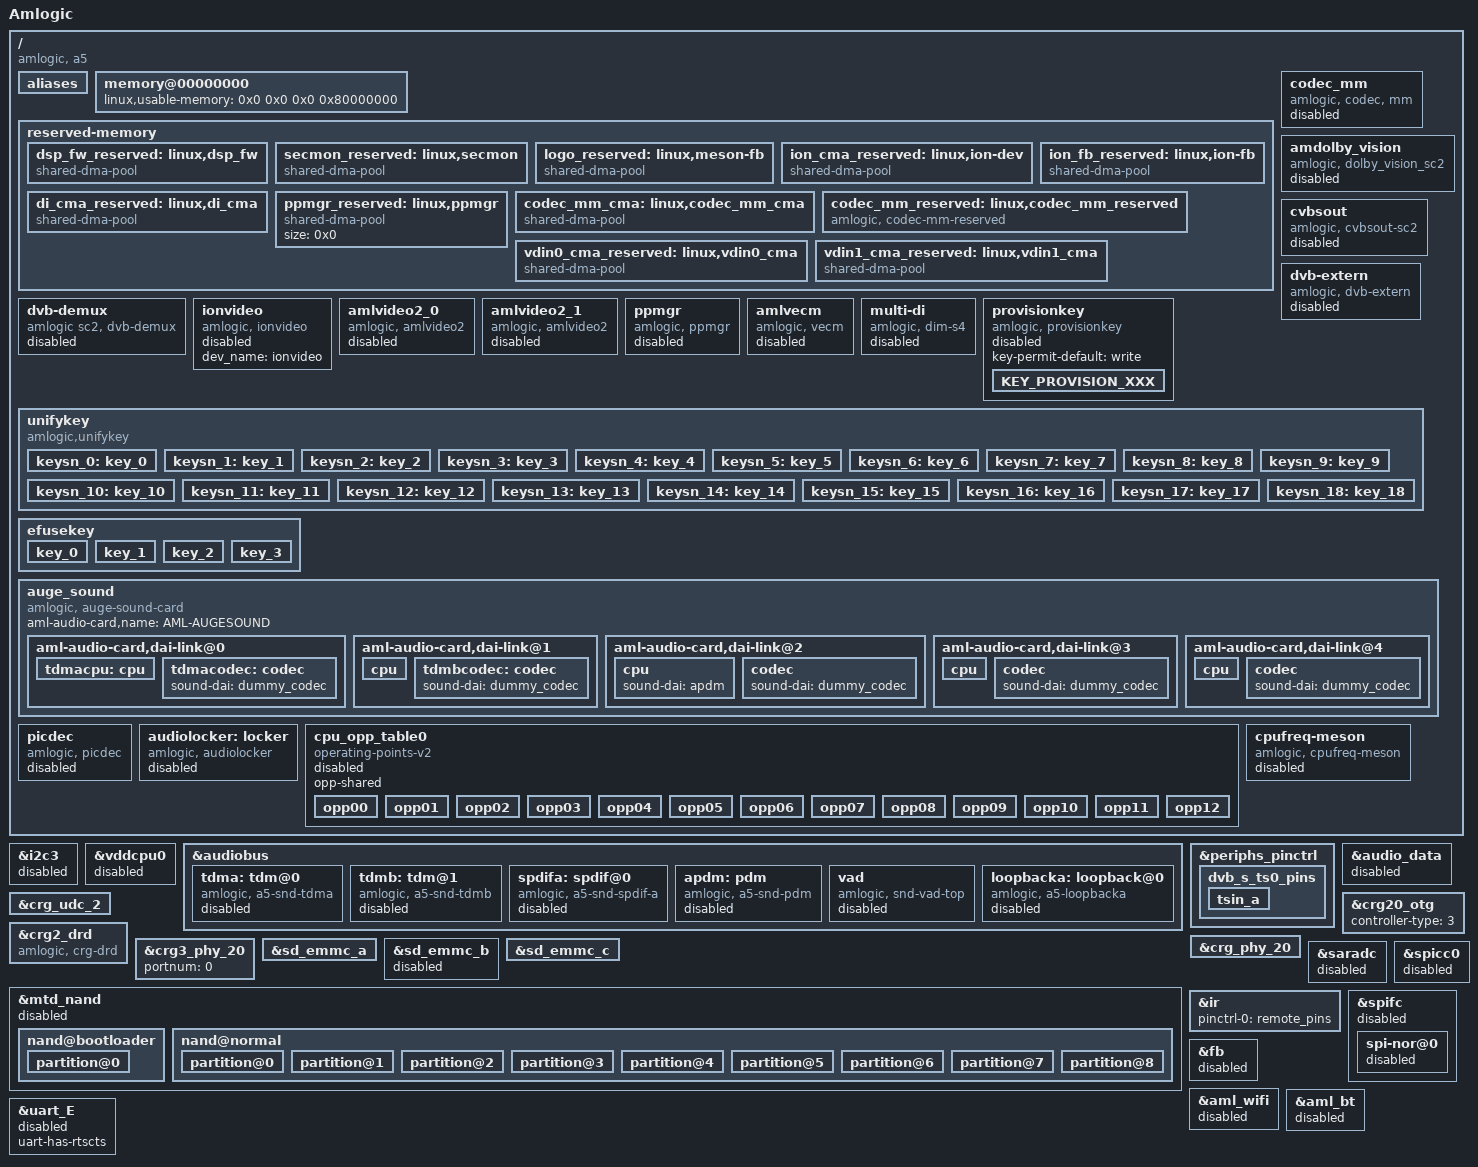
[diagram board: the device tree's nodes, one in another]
// SPDX-License-Identifier: (GPL-2.0+ OR MIT)
/*
 * Copyright (c) 2019 Amlogic, Inc. All rights reserved.
 */

/dts-v1/;

#include "meson-a5.dtsi"
#include "partition_mbox_ab.dtsi"
#include <dt-bindings/input/input.h>

/ {
	model = "Amlogic";
	amlogic-dt-id = "a5_pxp";
	compatible = "amlogic, a5";
	interrupt-parent = <&gic>;
	#address-cells = <2>;
	#size-cells = <2>;

	aliases {
		serial0 = &uart_B;
		serial1 = &uart_E;
		serial2 = &uart_C;
		serial3 = &uart_D;
		serial4 = &uart_A;
		i2c0 = &i2c0;
		i2c1 = &i2c1;
		i2c2 = &i2c2;
		i2c3 = &i2c3;
		spi0 = &spifc;
		spi1 = &spicc0;
		tsensor0 = &p_tsensor;
	};

	memory@00000000 {
		device_type = "memory";
		linux,usable-memory = <0x0 0x0 0x0 0x80000000>;
	};

	reserved-memory {
		#address-cells = <2>;
		#size-cells = <2>;
		ranges;

		dsp_fw_reserved:linux,dsp_fw {
			compatible = "shared-dma-pool";
			reusable;
			size = <0x0 0x00800000>;
			alignment = <0x0 0x00400000>;
			alloc-ranges = <0x0 0x30000000 0x0 0x00800000>;
		};

		secmon_reserved:linux,secmon {
			compatible = "shared-dma-pool";
			reusable;
			size = <0x0 0x3400000>;
			alignment = <0x0 0x400000>;
			alloc-ranges = <0x0 0x05000000 0x0 0x3400000>;
		};

		logo_reserved:linux,meson-fb {
			compatible = "shared-dma-pool";
			reusable;
			size = <0x0 0x800000>;
			alignment = <0x0 0x400000>;
			alloc-ranges = <0x0 0x7f800000 0x0 0x800000>;
		};

		ion_cma_reserved:linux,ion-dev {
			compatible = "shared-dma-pool";
			reusable;
			size = <0x0 0x6400000>;
			alignment = <0x0 0x400000>;
		};
		ion_fb_reserved:linux,ion-fb {
			compatible = "shared-dma-pool";
			reusable;
			/* 1920x1080x4x3 round up 4M align */
			size = <0x0 0x1c00000>;
			alignment = <0x0 0x400000>;
		};
		/*di CMA pool */
		di_cma_reserved:linux,di_cma {
			compatible = "shared-dma-pool";
			reusable;
			/* buffer_size = 3621952(yuv422 8bit)
			 *  | 4736064(yuv422 10bit)
			 *  | 4074560(yuv422 10bit full pack mode)
			 * 10x3621952=34.6M(0x23) support 8bit
			 * 10x4736064=45.2M(0x2e) support 12bit
			 * 10x4074560=40M(0x28) support 10bit
			 */
			//size = <0x0 0x0B000000>;
			//size = <0x0 0x0>;
			alignment = <0x0 0x400000>;
		};

		/*  POST PROCESS MANAGER */
		ppmgr_reserved:linux,ppmgr {
			compatible = "shared-dma-pool";
			size = <0x0>;
		};

		codec_mm_cma:linux,codec_mm_cma {
			compatible = "shared-dma-pool";
			reusable;
			/* ion_codec_mm max can alloc size 80M*/
			size = <0x0 0xd000000>;
			alignment = <0x0 0x400000>;
			linux,contiguous-region;
		};

		/* codec shared reserved */
		codec_mm_reserved:linux,codec_mm_reserved {
			compatible = "amlogic, codec-mm-reserved";
			size = <0x0 0x0>;
			alignment = <0x0 0x100000>;
			//no-map;
		};

		/*  vdin0 CMA pool */
		vdin0_cma_reserved:linux,vdin0_cma {
			compatible = "shared-dma-pool";
			reusable;
			/* up to 1920x1080 yuv422 8bit and 5 buffers
			 * 1920x1080x2x5 = 20 M
			 */
			size = <0x0 0x01400000>;
			alignment = <0x0 0x400000>;
		};
		/*  vdin1 CMA pool */
		vdin1_cma_reserved:linux,vdin1_cma {
			compatible = "shared-dma-pool";
			reusable;
			/* up to 1920x1080 yuv422 8bit and 5 buffers
			 * 1920x1080x2x5 = 20 M
			 */
			size = <0x0 0x01400000>;
			alignment = <0x0 0x400000>;
		};
	};
	codec_mm {
		compatible = "amlogic, codec, mm";
		memory-region = <&codec_mm_cma &codec_mm_reserved>;
		dev_name = "codec_mm";
		status = "disabled";
	};
	amdolby_vision {
		compatible = "amlogic, dolby_vision_sc2";
		dev_name = "aml_amdolby_vision_driver";
		status = "disabled";
		tv_mode = <0>;/*1:enabel ;0:disable*/
	};
	cvbsout {
		compatible = "amlogic, cvbsout-sc2";
		status = "disabled";

		/* clk path */
		/* 0:vid_pll vid2_clk */
		/* 1:gp0_pll vid2_clk */
		/* 2:vid_pll vid1_clk */
		/* 3:gp0_pll vid1_clk */
		clk_path = <0>;

		/* performance: reg_address, reg_value */
		/* tm2 */
		performance = <0x1bf0  0x9
			0x1b56  0x333
			0x1b12  0x8080
			0x1b05  0xfd
			0x1c59  0xf850
			0xffff  0x0>; /* ending flag */
		performance_sarft = <0x1bf0  0x9
			0x1b56  0x333
			0x1b12  0x0
			0x1b05  0x9
			0x1c59  0xfc48
			0xffff  0x0>; /* ending flag */
		performance_revB_telecom = <0x1bf0  0x9
			0x1b56  0x546
			0x1b12  0x8080
			0x1b05  0x9
			0x1c59  0xf850
			0xffff  0x0>; /* ending flag */
	};

	dvb-extern {
		compatible = "amlogic, dvb-extern";
		dev_name = "dvb-extern";
		status = "disabled";

		/* dvb hardware main power. */
		dvb_power_gpio = <&gpio GPIOZ_5 GPIO_ACTIVE_HIGH>;
		dvb_power_value = <1>;
		dvb_power_dir = <0>; /* 0: out, 1: in. */

		fe_num = <3>; /* interal 2 * dvb-c, extern 1 * dvb-s */
		fe0_demod = "internal";
		fe0_tuner0 = <0>; /* use tuner0 */

		fe1_demod = "internal";
		fe1_tuner0 = <1>; /* use tuner1 */

		fe2_demod = "cxd2856";
		//fe2_i2c_adap_id = <&i2c4>;
		fe2_demod_i2c_addr = <0xD8>;
		fe2_reset_value = <0>;
		fe2_reset_gpio = <&gpio GPIOZ_4 GPIO_ACTIVE_HIGH>;
		fe2_reset_dir = <0>; /* 0: out, 1: in. */
		fe2_ant_poweron_value = <0>;
		//fe2_ant_power_gpio = <&gpio GPIOH_9 GPIO_ACTIVE_HIGH>;
		fe2_ts = <0>;
		fe2_tuner1 = <3>; /* use tuner3, only S. */

		tuner_num = <4>; /* tuner number, multi tuner support */
		tuner0_name = "r836_tuner";
		tuner0_i2c_adap = <&i2c3>;
		tuner0_i2c_addr = <0x1a>; /* 7bit */
		tuner0_xtal = <0>; /* 0: 16MHz, 1: 24MHz */
		tuner0_xtal_mode = <0>;
					/* NO_SHARE_XTAL(0)
					 * SLAVE_XTAL_SHARE(3)
					 */
		tuner0_xtal_cap = <16>;
		tuner0_lt_out = <1>;

		tuner1_name = "r836_tuner";
		tuner1_i2c_adap = <&i2c3>;
		tuner1_i2c_addr = <0x3a>; /* 7bit */
		tuner1_xtal = <0>; /* 0: 16MHz, 1: 24MHz */
		tuner1_xtal_mode = <0>;
					/* NO_SHARE_XTAL(0)
					 * SLAVE_XTAL_SHARE(3)
					 */
		tuner1_xtal_cap = <16>;
		tuner1_lt_out = <1>;

		tuner2_name = "av2018_tuner";
		tuner2_i2c_adap = <&i2c3>;
		tuner2_i2c_addr = <0xC4>; /* 8bit */
		tuner2_lt_out = <1>;

		tuner3_name = "av2018_tuner";
		tuner3_lt_out = <1>;
	};

	dvb-demux {
		compatible = "amlogic sc2, dvb-demux";
		dev_name = "dvb-demux";
		status = "disabled";

		reg = <0x0 0xfe000000 0x0 0x480000>;

		dmxdev_num = <4>;

		tsn_from = "demod";

		/*single demod setting */
		ts0_sid = <0x20>;
		ts0 = "serial-4wire"; /* tsinA: serial-4wire, serial-3wire */
		ts0_control = <0x0>;
		ts0_invert = <0>;

		ts1_sid = <0x21>;
		ts1 = "parallel";
		ts1_control = <0x0>;
		ts1_invert = <0>;

		ts2_sid = <0x22>;
		ts2 = "parallel";
		ts2_control = <0x0>;
		ts2_invert = <0>;

		pinctrl-names = "s_ts0";
		pinctrl-0 = <&dvb_s_ts0_pins>;
	};

	ionvideo {
		compatible = "amlogic, ionvideo";
		dev_name = "ionvideo";
		status = "disabled";
	};

	amlvideo2_0 {
		compatible = "amlogic, amlvideo2";
		dev_name = "amlvideo2";
		status = "disabled";
		amlvideo2_id = <0>;
		cma_mode = <1>;
	};

	amlvideo2_1 {
		compatible = "amlogic, amlvideo2";
		dev_name = "amlvideo2";
		status = "disabled";
		amlvideo2_id = <1>;
		cma_mode = <1>;
	};

	ppmgr {
		compatible = "amlogic, ppmgr";
		memory-region = <&ppmgr_reserved>;
		dev_name = "ppmgr";
		status = "disabled";
	};

	amlvecm {
		compatible = "amlogic, vecm";
		dev_name = "aml_vecm";
		status = "disabled";
		gamma_en = <0>;/*1:enabel ;0:disable*/
		wb_en = <0>;/*1:enabel ;0:disable*/
		cm_en = <0>;/*1:enabel ;0:disable*/
		/*0: 709/601  1: bt2020*/
		tx_op_color_primary = <0>;
	};

	multi-di {
		compatible = "amlogic, dim-s4";
		status = "disabled";
		/* 0:use reserved; 1:use cma; 2:use cma as reserved */
		flag_cma = <4>;	//<1>;
		//memory-region = <&di_reserved>;
		//memory-region = <&di_cma_reserved>;
		interrupts = <0 203 1
				0 202 1>;
		interrupt-names = "pre_irq", "post_irq";
		//clocks = <&clkc CLKID_VPU_CLKB>,
		//	<&clkc CLKID_VPU>;
		//clock-names = "vpu_clkb",
		//	"vpu_mux";
		//clock-range = <334 667>;
		/* buffer-size = <3621952>;(yuv422 8bit) */
		buffer-size = <4074560>;/*yuv422 fullpack*/
		/* reserve-iomap = "true"; */
		/* if enable nr10bit, set nr10bit-support to 1 */
		post-wr-support = <1>;
		nr10bit-support = <1>;
		nrds-enable = <1>;
		pps-enable = <1>;
	};

	provisionkey {
		compatible = "amlogic, provisionkey";
		status = "disabled";
		key-permit-default = "write";
		//new key not need add dts if started with KEY_PROVISION_
		KEY_PROVISION_XXX { };
		//test_my_added_keyname { };
	};//End provisionkey

	unifykey{
		compatible = "amlogic,unifykey";
		status = "okay";
		unifykey-num = <19>;
		unifykey-index-0 = <&keysn_0>;
		unifykey-index-1 = <&keysn_1>;
		unifykey-index-2 = <&keysn_2>;
		unifykey-index-3 = <&keysn_3>;
		unifykey-index-4 = <&keysn_4>;
		unifykey-index-5 = <&keysn_5>;
		unifykey-index-6 = <&keysn_6>;
		unifykey-index-7 = <&keysn_7>;
		unifykey-index-8 = <&keysn_8>;
		unifykey-index-9 = <&keysn_9>;
		unifykey-index-10= <&keysn_10>;
		unifykey-index-11= <&keysn_11>;
		unifykey-index-12= <&keysn_12>;
		unifykey-index-13= <&keysn_13>;
		unifykey-index-14= <&keysn_14>;
		unifykey-index-15= <&keysn_15>;
		unifykey-index-16= <&keysn_16>;
		unifykey-index-17= <&keysn_17>;
		unifykey-index-18= <&keysn_18>;

		keysn_0: key_0{
			key-name = "usid";
			key-device = "normal";
			key-permit = "read","write","del";
		};
		keysn_1:key_1{
			key-name = "mac";
			key-device = "normal";
			key-permit = "read","write","del";
		};
		keysn_2:key_2{
			key-name = "hdcp";
			key-device = "secure";
			key-type = "sha1";
			key-permit = "read","write","del";
		};
		keysn_3:key_3{
			key-name = "secure_boot_set";
			key-device = "efuse";
			key-permit = "write";
		};
		keysn_4:key_4{
			key-name = "mac_bt";
			key-device = "normal";
			key-permit = "read","write","del";
			key-type  = "mac";
		};
		keysn_5:key_5{
			key-name = "mac_wifi";
			key-device = "normal";
			key-permit = "read","write","del";
			key-type = "mac";
		};
		keysn_6:key_6{
			key-name = "hdcp2_tx";
			key-device = "normal";
			key-permit = "read","write","del";
		};
		keysn_7:key_7{
			key-name = "hdcp2_rx";
			key-device = "normal";
			key-permit = "read","write","del";
		};
		keysn_8:key_8{
			key-name = "widevinekeybox";
			key-device = "secure";
			key-permit = "read","write","del";
		};
		keysn_9:key_9{
			key-name = "deviceid";
			key-device = "normal";
			key-permit = "read","write","del";
		};
		keysn_10:key_10{
			key-name = "hdcp22_fw_private";
			key-device = "secure";
			key-permit = "read","write","del";
		};
		keysn_11:key_11{
			key-name = "PlayReadykeybox25";
			key-device = "secure";
			key-permit = "read","write","del";
		};
		keysn_12:key_12{
			key-name = "prpubkeybox";// PlayReady
			key-device = "secure";
			key-permit = "read","write","del";
		};
		keysn_13:key_13{
			key-name = "prprivkeybox";// PlayReady
			key-device = "secure";
			key-permit = "read","write","del";
		};
		keysn_14:key_14{
			key-name = "attestationkeybox";// attestation key
			key-device = "secure";
			key-permit = "read","write","del";
		};
		keysn_15:key_15{
			key-name = "region_code";
			key-device = "normal";
			key-permit = "read","write","del";
		};
		keysn_16:key_16{
			key-name = "netflix_mgkid";
			key-device = "secure";
			key-permit = "read","write","del";
		};
		keysn_17:key_17{
			key-name = "attestationdevidbox";// attest dev id box
			key-device = "secure";
			key-permit = "read","write","del";
		};
		keysn_18:key_18{
			key-name = "oemkey";
			key-device = "normal";
			key-permit = "read","write","del";
		};
	};//End unifykey

	efusekey:efusekey{
		keynum = <4>;
		key0 = <&key_0>;
		key1 = <&key_1>;
		key2 = <&key_2>;
		key3 = <&key_3>;
		key_0:key_0{
			keyname = "mac";
			offset = <0>;
			size = <6>;
		};
		key_1:key_1{
			keyname = "mac_bt";
			offset = <6>;
			size = <6>;
		};
		key_2:key_2{
			keyname = "mac_wifi";
			offset = <12>;
			size = <6>;
		};
		key_3:key_3{
			keyname = "usid";
			offset = <18>;
			size = <16>;
		};
	};//End efusekey
	/* Audio Related start */
	auge_sound {
		compatible = "amlogic, auge-sound-card";
		aml-audio-card,name = "AML-AUGESOUND";

		/*avout mute gpio*/
		//avout_mute-gpios = <&gpio GPIOH_5 GPIO_ACTIVE_HIGH>;
		//spk_mute-gpios = <&gpio GPIOD_2 GPIO_ACTIVE_LOW>;

		aml-audio-card,dai-link@0 {
			format = "i2s";
			mclk-fs = <256>;
			//continuous-clock;
			//bitclock-inversion;
			//frame-inversion;
			/* master mode */
			bitclock-master = <&tdma>;
			frame-master = <&tdma>;
			/* slave mode */
			/*
			 * bitclock-master = <&tdmacodec>;
			 * frame-master = <&tdmacodec>;
			 */
			suffix-name = "alsaPORT-pcm";
			tdmacpu: cpu {
				sound-dai = <&tdma>;
				dai-tdm-slot-tx-mask =
							<1 1>;
				dai-tdm-slot-rx-mask =
							<1 1>;
				dai-tdm-slot-num = <2>;
				dai-tdm-slot-width = <32>;
				system-clock-frequency = <12288000>;
			};
			tdmacodec: codec {
				sound-dai = <&dummy_codec>;
			};
		};

		aml-audio-card,dai-link@1 {
			format = "i2s";// "dsp_a";
			mclk-fs = <256>;
			//continuous-clock;
			//bitclock-inversion;
			//frame-inversion;
			/* master mode */
			bitclock-master = <&tdmb>;
			frame-master = <&tdmb>;
			/* slave mode */
			//bitclock-master = <&tdmbcodec>;
			//frame-master = <&tdmbcodec>;
			/* suffix-name, sync with android audio hal
			 * what's the dai link used for
			 */
			suffix-name = "alsaPORT-i2s";
			cpu {
				sound-dai = <&tdmb>;
				dai-tdm-slot-tx-mask = <1 1>;
				//dai-tdm-slot-rx-mask = <1 1>;
				dai-tdm-slot-num = <2>;
				/*
				 * dai-tdm-slot-tx-mask =
				 *	<1 1 1 1 1 1 1 1>;
				 * dai-tdm-slot-rx-mask =
				 *	<1 1 1 1 1 1 1 1>;
				 * dai-tdm-slot-num = <8>;
				 */
				dai-tdm-slot-width = <32>;
				system-clock-frequency = <12288000>;
			};
			tdmbcodec: codec {
				sound-dai = <&dummy_codec /* &amlogic_codec */ /*&ad82584f_62*/>;
			};
		};

		aml-audio-card,dai-link@2 {
			mclk-fs = <64>;
			/* suffix-name, sync with android audio hal
			 * what's the dai link used for
			 */
			suffix-name = "alsaPORT-pdm-builtinmic";
			cpu {
				sound-dai = <&apdm>;
			};
			codec {
				sound-dai = <&dummy_codec>;
			};
		};

		aml-audio-card,dai-link@3 {
			mclk-fs = <128>;
			/* suffix-name, sync with android audio hal used for */
			suffix-name = "alsaPORT-spdif";
			cpu {
				sound-dai = <&spdifa>;
				system-clock-frequency = <6144000>;
			};
			codec {
				sound-dai = <&dummy_codec>;
			};
		};

		aml-audio-card,dai-link@4 {
			mclk-fs = <256>;
			continuous-clock;
			suffix-name = "alsaPORT-loopback";
			cpu {
				sound-dai = <&loopbacka>;
				system-clock-frequency = <12288000>;
			};
			codec {
				sound-dai = <&dummy_codec>;
			};
		};
	};

	picdec {
		compatible = "amlogic, picdec";
		status = "disabled";
	};

	audiolocker: locker {
		compatible = "amlogic, audiolocker";
		clock-names = "lock_out", "lock_in", "out_src",
					"in_src", "out_calc", "in_ref";
		interrupts = <GIC_SPI 1 IRQ_TYPE_EDGE_RISING>;
		interrupt-names = "irq";
		frequency = <49000000>; /* pll */
		dividor = <49>; /* locker's parent */
		status = "disabled";
	};/* Audio Related end */

	cpu_opp_table0: cpu_opp_table0 {
		compatible = "operating-points-v2";
		status = "disabled";
		opp-shared;

		opp00 {
			opp-hz = /bits/ 64 <100000000>;
			opp-microvolt = <779000>;
		};
		opp01 {
			opp-hz = /bits/ 64 <250000000>;
			opp-microvolt = <779000>;
		};
		opp02 {
			opp-hz = /bits/ 64 <500000000>;
			opp-microvolt = <779000>;
		};
		opp03 {
			opp-hz = /bits/ 64 <667000000>;
			opp-microvolt = <799000>;
		};
		opp04 {
			opp-hz = /bits/ 64 <1000000000>;
			opp-microvolt = <819000>;
		};
		opp05 {
			opp-hz = /bits/ 64 <1200000000>;
			opp-microvolt = <829000>;
		};
		opp06 {
			opp-hz = /bits/ 64 <1404000000>;
			opp-microvolt = <839000>;
		};
		opp07 {
			opp-hz = /bits/ 64 <1500000000>;
			opp-microvolt = <849000>;
		};
		opp08 {
			opp-hz = /bits/ 64 <1608000000>;
			opp-microvolt = <879000>;
		};
		opp09 {
			opp-hz = /bits/ 64 <1704000000>;
			opp-microvolt = <919000>;
		};
		opp10 {
			opp-hz = /bits/ 64 <1800000000>;
			opp-microvolt = <959000>;
		};
		opp11 {
			opp-hz = /bits/ 64 <1908000000>;
			opp-microvolt = <1019000>;
		};
		opp12 {
			opp-hz = /bits/ 64 <2004000000>;
			opp-microvolt = <1049000>;
		};
	};

	cpufreq-meson {
		compatible = "amlogic, cpufreq-meson";
		status = "disabled";
	};
};

&i2c3 {
	status = "disabled";
	pinctrl-names="default";
	pinctrl-0=<&i2c3_pins2>;
	clock-frequency = <300000>;
};

&vddcpu0 {
	status = "disabled";
};

&audiobus {
	tdma: tdm@0 {
		compatible = "amlogic, a5-snd-tdma";
		#sound-dai-cells = <0>;
		dai-tdm-lane-slot-mask-in = <0 1>;
		dai-tdm-lane-slot-mask-out = <1 0>;
		dai-tdm-clk-sel = <0>;
		clocks = <&clkaudio CLKID_AUDIO_MCLK_A
				&clkc CLKID_MPLL0>;
		clock-names = "mclk", "clk_srcpll";

		status = "disabled";
	};

	tdmb: tdm@1 {
		compatible = "amlogic, a5-snd-tdmb";
		#sound-dai-cells = <0>;
		dai-tdm-lane-slot-mask-out = <1 1 1 1>;
		dai-tdm-clk-sel = <1>;
		clocks = <&clkaudio CLKID_AUDIO_MCLK_B
				&clkc CLKID_MPLL1>;
		clock-names = "mclk", "clk_srcpll";

		status = "disabled";
	};

	spdifa: spdif@0 {
		compatible = "amlogic, a5-snd-spdif-a";
		#sound-dai-cells = <0>;
		clocks = <&clkc CLKID_MPLL0
				&clkc CLKID_FCLK_DIV4
				&clkaudio CLKID_AUDIO_GATE_SPDIFIN
				&clkaudio CLKID_AUDIO_GATE_SPDIFOUT_A
				&clkaudio CLKID_AUDIO_SPDIFIN
				&clkaudio CLKID_AUDIO_SPDIFOUT_A>;
		clock-names = "sysclk", "fixed_clk", "gate_spdifin",
				"gate_spdifout", "clk_spdifin", "clk_spdifout";
		interrupts =
				<GIC_SPI 35 IRQ_TYPE_EDGE_RISING>;

		interrupt-names = "irq_spdifin";
		//pinctrl-names = "spdif_pins", "spdif_pins_mute";
		//pinctrl-0 = <&spdifout>;
		//pinctrl-1 = <&spdifout_a_mute>;

		/*spdif clk tuning enable*/
		clk_tuning_enable = <1>;

		status = "disabled";
	};

	apdm: pdm {
		compatible = "amlogic, a5-snd-pdm";
		#sound-dai-cells = <0>;

		clocks = <&clkaudio CLKID_AUDIO2_GATE_PDM
			&clkc CLKID_FCLK_DIV4
			&clkc CLKID_FCLK_DIV4
			&clkaudio CLKID_AUDIO2_PDM_DCLK
			&clkaudio CLKID_AUDIO2_PDM_SYSCLK>;
		clock-names = "gate",
			"sysclk_srcpll",
			"dclk_srcpll",
			"pdm_dclk",
			"pdm_sysclk";

		//pinctrl-names = "pdm_pins";
		//pinctrl-0 = <&pdmin>;

		/* mode 0~4, defalut:1 */
		filter_mode = <1>;

		status = "disabled";
	};
#if 0
	asrca: resample@0 {
		compatible = "amlogic, t5-resample-a";
		clocks = <&clkc CLKID_MPLL3
				&clkaudio CLKID_AUDIO_MCLK_F
				&clkaudio CLKID_AUDIO_RESAMPLE_A>;
		clock-names = "resample_pll", "resample_src", "resample_clk";
		/*same with toddr_src
		 *	TDMIN_A, 0
		 *	TDMIN_B, 1
		 *	TDMIN_C, 2
		 *	SPDIFIN, 3
		 *	PDMIN,  4
		 *	NONE,
		 *	TDMIN_LB, 6
		 *	LOOPBACK, 7
		 */
		resample_module = <4>;
		status = "disabled";
	};
#endif
	vad:vad {
		compatible = "amlogic, snd-vad-top";
		#sound-dai-cells = <0>;

		clocks = <&clkaudio CLKID_AUDIO2_GATE_TOVAD
			&clkc CLKID_FCLK_DIV4
			&clkaudio CLKID_AUDIO2_VAD_CLK>;
		clock-names = "gate", "pll", "clk";

		interrupts = <GIC_SPI 39 IRQ_TYPE_EDGE_RISING
				GIC_SPI 44 IRQ_TYPE_EDGE_RISING>;
		interrupt-names = "irq_wakeup", "irq_frame_sync";

		/*
		 * Data src sel:
		 * 0: tdmin_a;
		 * 1: tdmin_b;
		 * 2: tdmin_c;
		 * 3: spdifin;
		 * 4: pdmin;
		 * 5: loopback_b;
		 * 6: tdmin_lb;
		 * 7: loopback_a;
		 */
		src = <4>;

		/*
		 * deal with hot word in user space or kernel space
		 * 0: in user space
		 * 1: in kernel space
		 */
		level = <1>;

		status = "disabled";
	};

	loopbacka:loopback@0 {
		compatible = "amlogic, a5-loopbacka";
		#sound-dai-cells = <0>;

		clocks = <&clkaudio CLKID_AUDIO2_GATE_PDM
			&clkc CLKID_FCLK_DIV4
			&clkc CLKID_FCLK_DIV4
			&clkaudio CLKID_AUDIO2_PDM_DCLK
			&clkaudio CLKID_AUDIO2_PDM_SYSCLK
			&clkc CLKID_MPLL0
			&clkaudio CLKID_AUDIO_MCLK_A>;
		clock-names = "pdm_gate",
			"pdm_sysclk_srcpll",
			"pdm_dclk_srcpll",
			"pdm_dclk",
			"pdm_sysclk",
			"tdminlb_mpll",
			"tdminlb_mclk";

		/* datain src
		 * 0: tdmin_a;
		 * 1: tdmin_b;
		 * 2: tdmin_c;
		 * 3: spdifin;
		 * 4: pdmin;
		 */
		datain_src = <4>;
		datain_chnum = <0>;
		datain_chmask = <0x0>;
		/* config which data pin for loopback */
		datain-lane-mask-in = <0 0 0 0>;

		/* calc mclk for datalb */
		mclk-fs = <256>;

		/* tdmin_lb src
		 * 0: tdmoutA
		 * 1: tdmoutB
		 * 2: tdmoutC
		 * 3: PAD_TDMINA_DIN*, refer to core pinmux
		 * 4: PAD_TDMINB_DIN*, refer to core pinmux
		 * 5: PAD_TDMINC_DIN*, refer to core pinmux
		 * 6: PAD_TDMINA_D*, oe, refer to core pinmux
		 * 7: PAD_TDMINB_D*, oe, refer to core pinmux
		 */
		/* if tdmin_lb >= 3, use external loopback */
		datalb_src = <1>;
		datalb_chnum = <2>;
		datalb_chmask = <0x3>;
		/* config which data pin as loopback */
		datalb-lane-mask-in = <1 0 0 0>;

		status = "disabled";
	};
#if 0
	aed:effect {
		compatible = "amlogic, snd-effect-v3";
		#sound-dai-cells = <0>;
		clocks = <&clkaudio CLKID_AUDIO_GATE_EQDRC
			&clkc CLKID_FCLK_DIV5
			&clkaudio CLKID_AUDIO_EQDRC>;
		clock-names = "gate", "srcpll", "eqdrc";
		/*
		 * 0:tdmout_a
		 * 1:tdmout_b
		 * 2:tdmout_c
		 * 3:spdifout
		 * 4:spdifout_b
		 */
		eqdrc_module = <1>;
		/* max 0xf, each bit for one lane, usually one lane */
		lane_mask = <0x1>;
		/* max 0xff, each bit for one channel */
		channel_mask = <0x3>;
		status = "disabled";
	};
#endif
}; /* end of audiobus */

&periphs_pinctrl {
#if 0
	tdm_a: tdm_a {
		mux { /* GPIOX_11, GPIOX_10, GPIOX_8, GPIOX_9 */
			groups = "tdm_sclk0",
				"tdm_fs0",
				"tdm_d3",
				"tdm_d4";
			function = "tdm";
		};
	};

	tdmin_a: tdmin_a {
		mux { /* GPIOX_8 */
			groups = "tdma_din1";
			function = "tdma_in";
		};
	};

	tdmb_mclk: tdmb_mclk {
		mux {
			groups = "mclk0_a";
			function = "mclk0";
			drive-strength = <2>;
		};
	};
	tdmout_b: tdmout_b {
		mux { /* GPIOA_1, GPIOA_2, GPIOA_3 */
			groups = "tdmb_sclk",
				"tdmb_fs",
				"tdmb_dout0";
			function = "tdmb_out";
			drive-strength = <2>;
		};
	};

	tdmin_b:tdmin_b {
		mux { /* GPIOA_4 */
			groups = "tdmb_din1"
				/*,"tdmb_slv_sclk", "tdmb_slv_fs"*/;
			function = "tdmb_in";
			drive-strength = <2>;
		};
	};

	tdmc_mclk: tdmc_mclk {
		mux { /* GPIOA_11 */
			groups = "mclk1_a";
			function = "mclk1";
		};
	};

	tdmout_c:tdmout_c {
		mux { /* GPIOA_12, GPIOA_13 */
			groups = "tdmc_sclk_a",
				"tdmc_fs_a"
				/*, "tdmc_dout0_a"
				 *,	"tdmc_dout2"
				 *, "tdmc_dout3"
				 */;
			function = "tdmc_out";
		};
	};

	tdmin_c:tdmin_c {
		mux { /* GPIOA_10 */
			groups = "tdmc_din0_a";
			function = "tdmc_in";
		};
	};

	spdifin: spdifin {
		mux {/* GPIOH_5 */
			groups = "spdif_in_h";
			function = "spdif_in";
		};
	};

	pdmin: pdmin {
		mux { /* GPIOC_0, GPIOC_4 */
			groups = "pdm_din0_c",
				"pdm_dclk_c";
			function = "pdm";
		};
	};

	spdifout: spdifout {
		mux { /* GPIOD_10 */
			groups = "spdif_out_d";
			function = "spdif_out";
		};
	};

	spdifout_a_mute: spdifout_a_mute {
		mux { /* GPIOD_10 */
			groups = "GPIOD_10";
			function = "gpio_periphs";
			output-low;
		};
	};
#endif
	dvb_s_ts0_pins: dvb_s_ts0_pins {
		tsin_a {
			groups = "tsin_a_sop",
				"tsin_a_valid",
				"tsin_a_clk",
				"tsin_a_din0";
			function = "tsin_a";
		};
	};
}; /* end of periphs_pinctrl */

&audio_data {
	status = "disabled";
};

&crg_udc_2 {
	status = "okay";
};

&crg20_otg {
	status = "okay";
	controller-type = <3>;
};

&crg2_drd {
	compatible = "amlogic, crg-drd";
	status = "okay";
};

&crg_phy_20 {
	status = "okay";
	portnum = <1>;
	gpio-vbus-power = "GPIOD_10";
	gpios = <&gpio GPIOD_10 GPIO_ACTIVE_HIGH>;
};

&crg3_phy_20 {
	status = "okay";
	portnum = <0>;
};

/* SDIO */
//&sd_emmc_a {
//	status = "okay";
//	pinctrl-0 = <&sdio_pins>;
//	pinctrl-1 = <&sdio_clk_gate_pins>;
//	pinctrl-names = "default", "clk-gate";
//	#address-cells = <1>;
//	#size-cells = <0>;
//
//	bus-width = <4>;
//	cap-sd-highspeed;
//	sd-uhs-sdr50;
//	sd_uhs-sdr104;
//	max-frequency = <200000000>;
//
//	non-removable;
//	disable-wp;
//
//	//vmmc-supply = <&vddao_3v3>;
//	//vqmmc-supply = <&vddio_ao1v8>;
//
//	brcmf: wifi@1 {
//		reg = <1>;
//		compatible = "brcm,bcm4329-fmac";
//	};
//};
/* SD card pxp bringup */
&sd_emmc_a {
	status = "okay";
	pinctrl-0 = <&sdcard_pins>;
	pinctrl-1 = <&sdcard_clk_gate_pins>;
	pinctrl-2 = <&sd_1bit_pins>;
	pinctrl-names = "sd_default",
			"clk-gate",
			"sd_1bit_pins";
	bus-width = <4>;
	cap-sd-highspeed;
	max-frequency = <200000000>;
	disable-wp;

	cd-gpios = <&gpio GPIOX_7 GPIO_ACTIVE_HIGH>;
	//vmmc-supply = <&vddao_3v3>;
	//vqmmc-supply = <&emmc_1v8>;
};

/* SD card */
&sd_emmc_b {
	status = "disabled";
	pinctrl-0 = <&sdcard_pins>;
	pinctrl-1 = <&sdcard_clk_gate_pins>;
	pinctrl-2 = <&sd_1bit_pins>;
	pinctrl-3 = <&sd_to_ao_uart_clr_pins
		&sdcard_pins &ao_to_sd_uart_pins>;
	pinctrl-4 = <&sd_to_ao_uart_clr_pins
		&sd_1bit_pins &ao_to_sd_uart_pins>;
	pinctrl-5 = <&sdcard_pins &ao_uart_pins>;
	pinctrl-6 = <&sd_to_ao_uart_clr_pins
		&ao_to_sd_uart_pins>;
	pinctrl-7 = <&sdcard_pins &ao_uart_pins>;
	pinctrl-8 = <&sd_to_ao_uart_clr_pins
		&ao_to_sd_uart_pins>;
	pinctrl-names = "sd_default",
			"clk-gate",
			"sd_1bit_pins",
			"sd_clk_cmd_uart_pins",
			"sd_1bit_uart_pins",
			"sd_to_ao_uart_pins",
			"ao_to_sd_uart_pins",
			"sd_to_ao_jtag_pins",
			"ao_to_sd_jtag_pins";
	bus-width = <4>;
	cap-sd-highspeed;
//	sd-uhs-sdr12;
//	sd-uhs-sdr25;
//	sd-uhs-sdr50;
//	sd_uhs-sdr104;
	max-frequency = <200000000>;
	disable-wp;

	cd-gpios = <&gpio GPIOC_6 GPIO_ACTIVE_HIGH>;
	dat1-gpios = <&gpio GPIOC_1 GPIO_ACTIVE_HIGH>;
	//vmmc-supply = <&vddao_3v3>;
	//vqmmc-supply = <&emmc_1v8>;
};

&sd_emmc_c {
	status = "okay";
	pinctrl-0 = <&emmc_pins>, <&emmc_ds_pins>;
	pinctrl-1 = <&emmc_clk_gate_pins>;
	pinctrl-names = "default", "clk-gate";

	bus-width = <8>;
	cap-mmc-highspeed;
	//mmc-ddr-1_8v;
//	mmc-hs200-1_8v;
//	mmc-hs400-1_8v;
	max-frequency = <200000000>;
	non-removable;
	disable-wp;

//	mmc-pwrseq = <&emmc_pwrseq>;
//	vmmc-supply = <&vddao_3v3>;
//	vqmmc-supply = <&vddao_1v8>;
};

&mtd_nand {
	status = "disabled";
	#address-cells = <1>;
	#size-cells = <0>;

	pinctrl-names = "nand_norb_mod","nand_cs_only";
	pinctrl-0 = <&all_nand_pins>;
	pinctrl-1 = <&nand_cs_pins>;
	bl_mode = <1>;
	fip_copies = <4>;
	fip_size = <0x200000>;
	ship_bad_block = <1>;
	disa_irq_flag = <1>;
	nand@bootloader {
		reg = <0>;
		#address-cells = <1>;
		#size-cells = <1>;
		nand-ecc-maximize;
		partition@0 {
			label = "bootloader";
			reg = <0x0 0x00000000>;
		};
	};
	nand@normal {
		reg = <0>;
		#address-cells = <1>;
		#size-cells = <1>;
		nand-ecc-maximize;

		partition@0 {
			label = "bl2e";
			reg = <0x0 0x00000000>;
		};
		partition@1 {
			label = "bl2x";
			reg = <0x0 0x00000000>;
		};
		partition@2 {
			label = "ddrfip";
			reg = <0x0 0x00000000>;
		};
		partition@3 {
			label = "tpl";
			reg = <0x0 0x00000000>;
		};
		partition@4 {
			label = "logo";
			reg = <0x0 0x00200000>;
		};
		partition@5 {
			label = "recovery";
			reg = <0x0 0x1000000>;
		};
		partition@6 {
			label = "boot";
			reg = <0x0 0x0F00000>;
		};
		partition@7 {
			label = "system";
			reg = <0x0 0x11800000>;
		};
		partition@8 {
			label = "data";
			reg = <0x0 0xffffffff>;
		};
	};
};

&saradc {
	status = "disabled";
};


&ir {
	status = "okay";
	pinctrl-0 = <&remote_pins>;
	pinctrl-names = "default";
};

&spicc0 {
	status = "disabled";
	pinctrl-names = "default";
	pinctrl-0 = <&spicc0_pins_x>;
	cs-gpios = <&gpio GPIOX_10 0>;
};

&spifc {
	status = "disabled";
	spi-nor@0 {
		status = "disabled";
	};
};

&fb {
	status = "disabled";
	display_size_default = <1920 1080 1920 2160 32>;
	mem_size = <0x00800000 0x1980000 0x100000>;
	logo_addr = "0x7f800000";
	mem_alloc = <0>;
	pxp_mode = <1>; /** 0:normal mode 1:pxp mode */
};

&aml_wifi{
	status = "disabled";
	interrupt-gpios = <&gpio  GPIOX_7  GPIO_ACTIVE_HIGH>;
	power_on-gpios = <&gpio   GPIOX_6  GPIO_ACTIVE_HIGH>;
};

&aml_bt {
	status = "disabled";
	reset-gpios = <&gpio    GPIOX_17 GPIO_ACTIVE_HIGH>;
	btwakeup-gpios = <&gpio    GPIOX_18 GPIO_ACTIVE_HIGH>;
	hostwake-gpios = <&gpio GPIOX_19 GPIO_ACTIVE_HIGH>;
};

&uart_E {
	status = "disabled";
	uart-has-rtscts;
};
